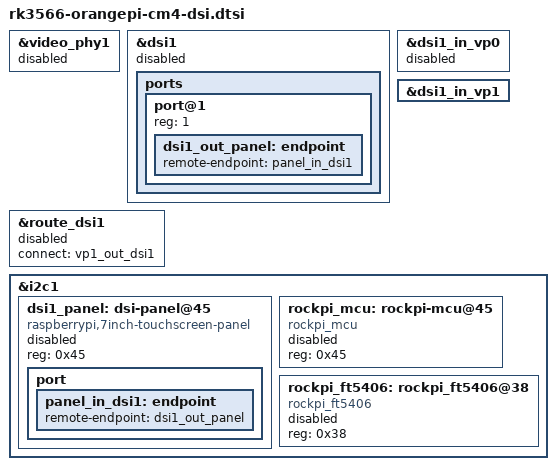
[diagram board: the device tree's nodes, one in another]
&video_phy1 {
        status = "disabled";
};

&dsi1 {
        status = "disabled";

        //dsi1_panel: dsi-panel@0 {
        //        compatible = "rockpi,tc358762";
        //        reg = <0x0>;
        //        status = "okay";

        //        ports {
        //                #address-cells = <1>;
        //                #size-cells = <0>;

        //                port@0 {
        //                        reg = <0>;

        //                        panel_in_dsi1: endpoint {
        //                                remote-endpoint = <&dsi1_out_panel>;
        //                        };
        //                };
        //        };
        //};

	ports {
		port@1 {
			reg = <1>;

			dsi1_out_panel: endpoint {
				remote-endpoint = <&panel_in_dsi1>;
			};
		};
	};
};

&dsi1_in_vp0 {
        status = "disabled";
};

&dsi1_in_vp1 {
        status = "okay";
};

&route_dsi1 {
        status = "disabled";
        connect = <&vp1_out_dsi1>;
};

&i2c1 {
        status = "okay";

        dsi1_panel: dsi-panel@45 {
                compatible = "raspberrypi,7inch-touchscreen-panel";
                reg = <0x45>;
                status = "disabled";

		port {
			panel_in_dsi1: endpoint {
				remote-endpoint = <&dsi1_out_panel>;
			};
		};
        };

        rockpi_mcu: rockpi-mcu@45 {
                compatible = "rockpi_mcu";
                reg = <0x45>;
                status = "disabled";
        };

        rockpi_ft5406: rockpi_ft5406@38 {
                compatible = "rockpi_ft5406";
                reg = <0x38>;
                status = "disabled";
        };

};
